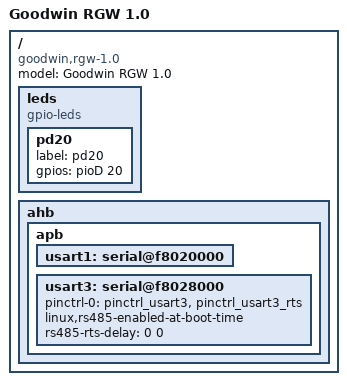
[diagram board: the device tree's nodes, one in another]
/*
 * goodwin-rgw-1.0.dts - Device Tree file for Goodwin RGW 1.0 board
 *
 *  Copyright (C) 2013 Goodwin,
 *                2013 Alexander Morozov <linux@meltdown.ru>
 *
 * Licensed under GPLv2 or later.
 */

/dts-v1/;
/include/ "goodwin-gw-9x25.dtsi"

/ {
	model = "Goodwin RGW 1.0";
	compatible = "goodwin,rgw-1.0", "atmel,at91sam9x5", "atmel,at91sam9";

	leds {
		compatible = "gpio-leds";
		pd20 {
			label = "pd20";
			gpios = <&pioD 20 0>;
		};
	};

	ahb {
		apb {
			/* GSM modem AUX */
			usart1: serial@f8020000 {
				status = "okay";
			};

			usart3: serial@f8028000 {
				status = "okay";
				pinctrl-0 = <&pinctrl_usart3 &pinctrl_usart3_rts>;
				linux,rs485-enabled-at-boot-time;
				rs485-rts-delay = <0 0>;
			};
		};
	};
};

